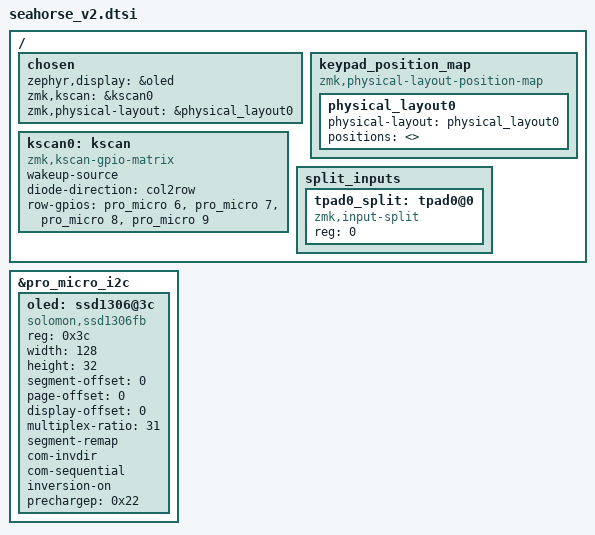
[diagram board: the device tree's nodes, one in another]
#include <dt-bindings/zmk/matrix_transform.h>

#include <physical_layouts.dtsi>
#include "seahorse_v2-layouts.dtsi"

/ {
	chosen {
		zephyr,display = &oled;
		zmk,kscan = &kscan0;
		// zmk,matrix-transform = &default_transform;
		zmk,physical-layout = &physical_layout0;
	};
	keypad_position_map {
        compatible = "zmk,physical-layout-position-map";

        physical_layout0 {
            physical-layout = <&physical_layout0>;
            positions = <>;
        };
    };

	kscan0: kscan {
		compatible = "zmk,kscan-gpio-matrix";
		wakeup-source;
		
		diode-direction = "col2row";
        row-gpios
            = <&pro_micro 6 (GPIO_ACTIVE_HIGH | GPIO_PULL_DOWN)> // row 0
            , <&pro_micro 7 (GPIO_ACTIVE_HIGH | GPIO_PULL_DOWN)> // row 1
            , <&pro_micro 8 (GPIO_ACTIVE_HIGH | GPIO_PULL_DOWN)> // row 2
            , <&pro_micro 9 (GPIO_ACTIVE_HIGH | GPIO_PULL_DOWN)> // row 3
            ;
	};

		split_inputs {
		  #address-cells = <1>;
		  #size-cells = <0>;

		  tpad0_split: tpad0@0 { compatible = "zmk,input-split"; reg = <0>; };
		};
	  

};
&pro_micro_i2c {
	status = "okay";

	oled: ssd1306@3c {
		compatible = "solomon,ssd1306fb";
		reg = <0x3c>;
		width = <128>;
		height = <32>;
		segment-offset = <0>;
		page-offset = <0>;
		display-offset = <0>;
		multiplex-ratio = <31>;
		segment-remap;
		com-invdir;
		com-sequential;
		inversion-on;
		prechargep = <0x22>;
	};
};
